# ZB204 register map
Vendor: GS; File version: 1.2
CPU: CM3 r2p0, little endian, MPU, no FPU, VTOR, 3 interrupt priority bits
Registers are 32-bit, read-write, reset 0x0 unless marked. A register's access mark holds for its fields unless they carry their own. Offsets are from the block's base; [hi:lo] are bit positions.

## SPI0 — Serial Peripheral Interface Module
Base 0x400A0000
Same registers: SPI1 0x400B0000
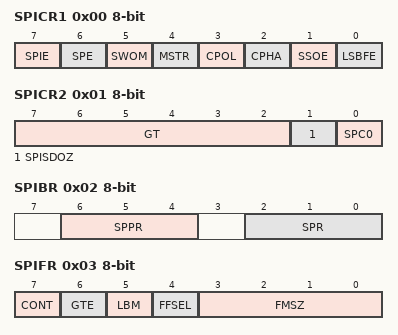
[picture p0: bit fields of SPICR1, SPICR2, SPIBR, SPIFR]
0x00 SPICR1 8-bit — SCI Integer Baud-Rate Divisor Register High
  [7] SPIE — SPI Interrupt Enable Bit
    0=SPIF and MODF interrupt requests disabled; 1=SPIF and MODF interrupt requests enabled
  [6] SPE — SPI System Enable Bit
    0=disabled; 1=enabled
  [5] SWOM — SPI Wired-OR Mode Bit
    0=Output buffers of SPI port pins [3:0] CMOS drive; 1=Output buffers of SPI port pins [3:0] open-drain
  [4] MSTR — Master Bit
    0=Slave mode; 1=Master mode
  [3] CPOL — Clock Polarity Bit
    0=Active-high clock; SCK idles low; 1=Active-low clock; SCK idles high
  [2] CPHA — Clock Phase Bit
    0=First SCK edge 1/2 cycle after start of transmission; 1=First SCK edge at start of transmission
  [1] SSOE — SPI System Enable Bit
  [0] LSBFE — SPI Interrupt Enable Bit
    0=Data transmitted MSB first; 1=Data transmitted LSB first
0x01 SPICR2 8-bit — SPI Control Register 2
  [7:2] GT — Guard Time Bits
  [1] SPISDOZ — SPI Stop in Doze Bit
    0=SPI active in doze mode; 1=SPI inactive in doze mode
  [0] SPC0 — SPI Stop in Doze Bit
    0=Even parity when PE = 1; 1=Odd parity when PE = 1
0x02 SPIBR 8-bit — SPI Baud Rate Register
  [6:4] SPPR — SPI Baud Rate Preselection Bits
  [2:0] SPR — SPI Baud Rate Bits
0x03 SPIFR 8-bit — SPI Frame Register
  [7] CONT — Continuous peripheral chip select enable
    0=Keep peripheral chip select signal low between transfers until EOTF is set; 1=Keep peripheral chip select signal low between transfers until EOTF is set
  [6] GTE — Guard Time Enable
    0=Guard Time is Disabled; 1=Guard Time is Enabled
  [5] LBM — Loop Back Mode
    0=Normal Mode; 1=Loop Back Mode
  [4] FFSEL — Frame Format Select
    0=FREESCALE frame format is selected; 1=Normal Mode
  [3:0] FMSZ — Frame Size
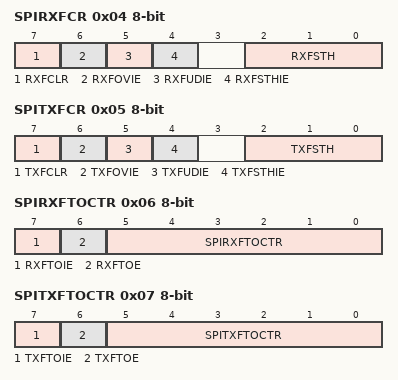
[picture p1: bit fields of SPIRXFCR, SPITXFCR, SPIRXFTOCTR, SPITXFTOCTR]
0x04 SPIRXFCR 8-bit — SPI RX FIFO Control Register
  [7] RXFCLR — RX FIFO Clear
    0=Read 0; 1=Write 1 to the bit will reset RXFIFO
  [6] RXFOVIE — RX FIFO Overflow Interrupt Enable
    0=Interrupt Disabled; 1=Interrupt Enabled
  [5] RXFUDIE — RX FIFO Underflow Interrupt Enable
    0=Interrupt Disabled; 1=Interrupt Enabled
  [4] RXFSTHIE — RX FIFO Service Threshold Interrupt Enable
    0=Interrupt Disabled; 1=Interrupt Enabled
  [2:0] RXFSTH — RX FIFO Service Threshold
0x05 SPITXFCR 8-bit — SPI TX FIFO Control Register
  [7] TXFCLR — TX FIFO Clear
    0=Read 0; 1=Write 1 to the bit will reset TXFIFO
  [6] TXFOVIE — TX FIFO Overflow Interrupt Enable
    0=Interrupt Disabled; 1=Interrupt Enabled
  [5] TXFUDIE — TX FIFO Underflow Interrupt Enable
    0=Interrupt Disabled; 1=Interrupt Enabled
  [4] TXFSTHIE — TX FIFO Service Threshold Interrupt Enable
    0=Interrupt Disabled; 1=Interrupt Enabled
  [2:0] TXFSTH — TX FIFO Service Threshold
0x06 SPIRXFTOCTR 8-bit — SPI RX FIFO TimeOut Counter Register
  [7] RXFTOIE — RX FIFO TimeOut Interrupt Enable
    0=RX FIFO TimeOut Interrupt Disabled; 1=RX FIFO TimeOut Interrupt Enabled
  [6] RXFTOE — RX FIFO TimeOut Function Enable
    0=RX FIFO TimeOut Function Disabled; 1=RX FIFO TimeOut Function Enabled
  [5:0] SPIRXFTOCTR — sets the SPI RX FIFO Timeout counter number
0x07 SPITXFTOCTR 8-bit — SPI TX FIFO TimeOut Counter Register
  [7] TXFTOIE — TX FIFO TimeOut Interrupt Enable
    0=TX FIFO TimeOut Interrupt Disabled; 1=TX FIFO TimeOut Interrupt Enabled
  [6] TXFTOE — TX FIFO TimeOut Function Enable
    0=TX FIFO TimeOut Function Disabled; 1=TX FIFO TimeOut Function Enabled
  [5:0] SPITXFTOCTR — sets the SPI TX FIFO Timeout counter number
0x08 SPIDDR 8-bit — SPI Port Data Direction Register
  [3:0] PORTSP — Data Direction Bits
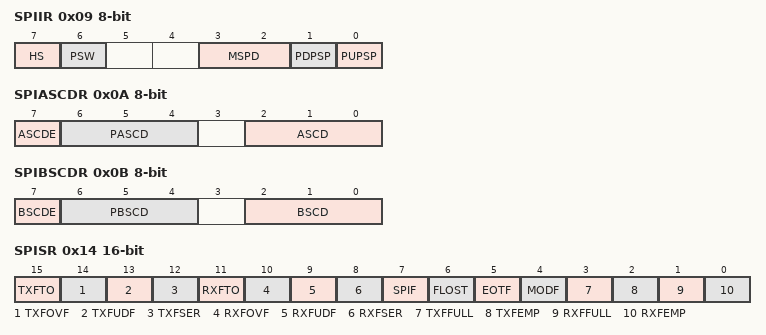
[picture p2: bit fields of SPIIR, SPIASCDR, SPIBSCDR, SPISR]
0x09 SPIIR 8-bit — SPI Interface Register
  [7] HS — High Speed Mode Enable in SPI slave mode
    0=High Speed Mode is disabled in SPI slave mode; 1=High Speed Mode is enabled in SPI slave mode
  [6] PSW — Pin Switch Bit
  [3:2] MSPD — SPI Master Sample Point Delay
  [1] PDPSP — SPI Port Reduced Drive Control Bit
  [0] PUPSP — SPI Port Pullup Enable Bit
    0=Pullup devices disabled for SPIPORT bits [3:0]; 1=Pullup devices enabled for SPIPORT bits [3:0]
0x0A SPIASCDR 8-bit — SPI After SCK Delay Register
  [7] ASCDE — After SCK Delay Enable
  [6:4] PASCD — After SCK Delay Enable
  [2:0] ASCD — SPI After SCK Delay Bits
    0=Disabled; 1=Enabled
0x0B SPIBSCDR 8-bit — SPI Before SCK Delay Register
  [7] BSCDE — Before SCK Delay Enable
  [6:4] PBSCD — SPI Before SCK Delay Preselection Bits
  [2:0] BSCD — SPI Before SCK Delay Bits
    0=Disabled; 1=Enabled
0x0C SPIPORT 8-bit — SPI Port Data Register
  [3:0] PORTSP — SPI Port Data Bits
0x0D SPITCNT_L 8-bit — SPI Transmit Counter Register
0x0E SPITCNT_H 16-bit — SPI Transmit Counter Register
0x10 SPIDR_L 8-bit — SPI Data Register
0x11 SPIDR_H 8-bit — SPI Data Register
0x14 SPISR 16-bit — SPI Status Register
  [all] fields
    0=Negative; 1=Active
  [15] TXFTO — TX FIFO TimeOut
  [14] TXFOVF — TX FIFO Overflow Flag
  [13] TXFUDF — TX FIFO Underflow Flag
  [12] TXFSER — TX FIFO Underflow Flag
  [11] RXFTO — RX FIFO TimeOut
  [10] RXFOVF — RX FIFO TimeOut
  [9] RXFUDF — RX FIFO Underflow Flag
  [8] RXFSER — RX FIFO Underflow Flag
  [7] SPIF — SPI Finish Flag
  [6] FLOST — Frame Lost
  [5] EOTF — End of Transmission Flag
  [4] MODF — Mode Fault Flag
  [3] TXFFULL — TX FIFO Full Flag
  [2] TXFEMP — TX FIFO empty Flag
  [1] RXFFULL — RX FIFO Full Flag
  [0] RXFEMP — RX FIFO empty Flag
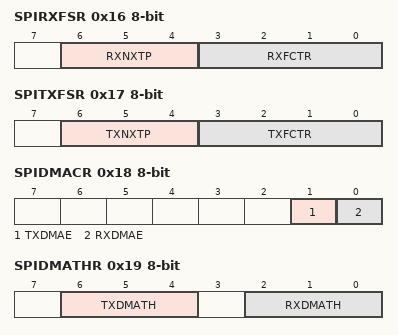
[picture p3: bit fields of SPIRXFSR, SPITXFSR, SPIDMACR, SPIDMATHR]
0x16 SPIRXFSR 8-bit — SPI RX FIFO Status Register
  [6:4] RXNXTP — RX Next Pointer
  [3:0] RXFCTR — RX FIFO Counter
0x17 SPITXFSR 8-bit — SPI TX FIFO Status Register
  [6:4] TXNXTP — TX Next Pointer
  [3:0] TXFCTR — TX FIFO Counter
0x18 SPIDMACR 8-bit — SPI DMA Control Register
  [1] TXDMAE — RX FIFO DMA request Enable
    0=Enabled; 1=Enabled
  [0] RXDMAE — SPI Interrupt Enable Bit
    0=Enabled; 1=Enabled
0x19 SPIDMATHR 8-bit — SPI DMA Threshold Register
  [6:4] TXDMATH — RX DMA Threshold
  [2:0] RXDMATH — RX DMA Threshold
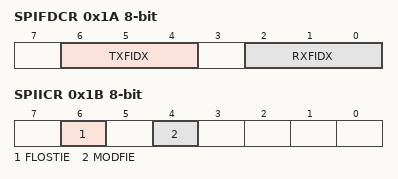
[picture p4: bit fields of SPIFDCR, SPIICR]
0x1A SPIFDCR 8-bit — SPI FIFO Debug Control Register
  [6:4] TXFIDX — TX FIFO Index
  [2:0] RXFIDX — RX FIFO Index
0x1B SPIICR 8-bit — SPI Interrupt Control Register
  [6] FLOSTIE — FLOST Interrupt Enable
    0=Enabled; 1=Enabled
  [4] MODFIE — MODF Interrupt Enable
    0=Enabled; 1=Enabled
0x1C SPIRXFDBGR 8-bit — SPI RX FIFO Debug Register
0x1D SPITXFDBGR 8-bit — SPI TX FIFO Debug Register
